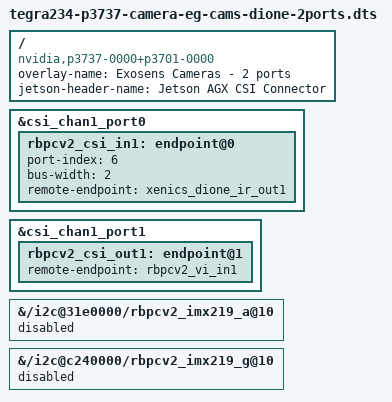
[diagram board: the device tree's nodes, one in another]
// SPDX-License-Identifier: GPL-2.0-only
// SPDX-FileCopyrightText: Copyright (c) 2023-2024, NVIDIA CORPORATION & AFFILIATES. All rights reserved.

/dts-v1/;
/plugin/;

#define EG_DISABLE_PORTS_23
#include "tegra234-p3737-camera-common-eg-cams-dione.dtsi"

/ {
	overlay-name = "Exosens Cameras - 2 ports";
	jetson-header-name = "Jetson AGX CSI Connector";
	compatible = "nvidia,p3737-0000+p3701-0000", "nvidia,p3737-0000+p3701-0004", "nvidia,p3737-0000+p3701-0005";

	/*
	 * NVCSI channel 1: per-channel endpoint numbering.
	 * Applied when IMX219 nodes are detected in /proc/device-tree (Auvidea 35.3.1).
	 * Channels 2 and 3 are absent from the Auvidea L4T 35.1 kernel DTB.
	 */
	fragment@1 {
		target = <&csi_chan1_port0>;
		__overlay__ {
			rbpcv2_csi_in1: endpoint@0 {
				status = "okay";
				port-index = <6>;
				bus-width = <2>;
				remote-endpoint = <&xenics_dione_ir_out1>;
			};
		};
	};

	fragment@2 {
		target = <&csi_chan1_port1>;
		__overlay__ {
			rbpcv2_csi_out1: endpoint@1 {
				status = "okay";
				remote-endpoint = <&rbpcv2_vi_in1>;
			};
		};
	};

	/*
	 * Disable the two IMX219 nodes that are present in the Auvidea 35.1 kernel
	 * DTB — the standalone disable-imx219 DTBO built for 4-port boards targets
	 * cam2/cam3 IMX219 paths (/i2c@c250000/..., /i2c@3180000/...) that do NOT
	 * exist on 2-port boards, so it fails with FDT_ERR_NOTFOUND. Fold the cam0
	 * and cam1 disable logic directly into the 2-port overlay.
	 */
	fragment@3 {
		target-path = "/i2c@31e0000/rbpcv2_imx219_a@10";
		__overlay__ {
			status = "disabled";
		};
	};

	fragment@4 {
		target-path = "/i2c@c240000/rbpcv2_imx219_g@10";
		__overlay__ {
			status = "disabled";
		};
	};

};
